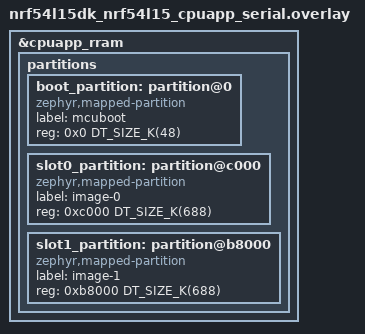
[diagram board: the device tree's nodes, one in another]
/*
 * Copyright (c) 2026 Nordic Semiconductor ASA
 *
 * SPDX-License-Identifier: LicenseRef-Nordic-5-Clause
 */

/*
 * Backward compatibility: pin the released NCS v2.8 slot geometry (previously
 * provided by Partition Manager) so slot0 start (0xc000) and end (0xb8000,
 * where the MCUboot image trailer lives) match what the v2.8 MCUboot on the
 * device expects. MCUboot itself keeps the default board map because only the
 * application update image is uploaded.
 */

/delete-node/ &boot_partition;
/delete-node/ &slot0_partition;
/delete-node/ &slot1_partition;
/delete-node/ &storage_partition;

&cpuapp_rram {
	partitions {
		boot_partition: partition@0 {
			compatible = "zephyr,mapped-partition";
			label = "mcuboot";
			reg = <0x0 DT_SIZE_K(48)>;
		};

		slot0_partition: partition@c000 {
			compatible = "zephyr,mapped-partition";
			label = "image-0";
			reg = <0xc000 DT_SIZE_K(688)>;
		};

		slot1_partition: partition@b8000 {
			compatible = "zephyr,mapped-partition";
			label = "image-1";
			reg = <0xb8000 DT_SIZE_K(688)>;
		};
	};
};
